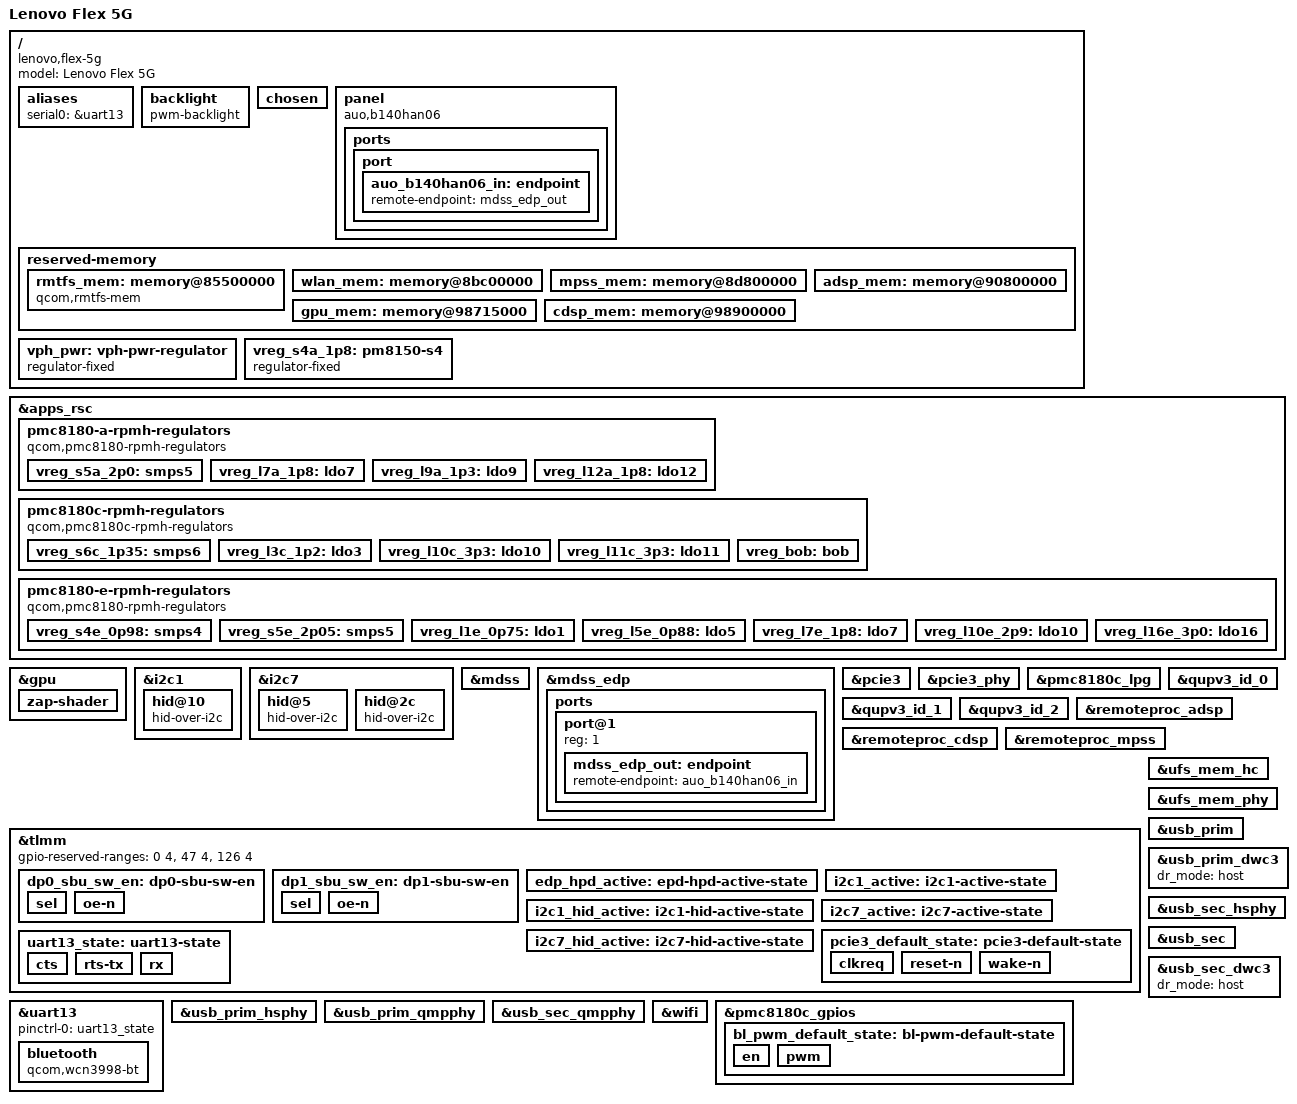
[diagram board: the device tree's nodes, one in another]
// SPDX-License-Identifier: BSD-3-Clause
/*
 * Copyright (c) 2017-2019, The Linux Foundation. All rights reserved.
 * Copyright (c) 2020-2021, Linaro Limited
 */

/dts-v1/;

#include <dt-bindings/regulator/qcom,rpmh-regulator.h>
#include <dt-bindings/gpio/gpio.h>
#include "sc8180x.dtsi"
#include "pmc8180.dtsi"
#include "pmc8180c.dtsi"

/ {
	model = "Lenovo Flex 5G";
	compatible = "lenovo,flex-5g", "qcom,sc8180x";

	aliases {
		serial0 = &uart13;
	};

	backlight: backlight {
		compatible = "pwm-backlight";
		pwms = <&pmc8180c_lpg 4 1000000>;
		enable-gpios = <&pmc8180c_gpios 8 GPIO_ACTIVE_HIGH>;

		pinctrl-names = "default";
		pinctrl-0 = <&bl_pwm_default_state>;
	};

	chosen {
	};

	panel {
		compatible = "auo,b140han06";
		no-hpd;

		backlight = <&backlight>;

		ports {
			port {
				auo_b140han06_in: endpoint {
					remote-endpoint = <&mdss_edp_out>;
				};
			};
		};
	};

	reserved-memory {
		rmtfs_mem: memory@85500000 {
			compatible = "qcom,rmtfs-mem";
			reg = <0x0 0x85500000 0x0 0x200000>;
			no-map;

			qcom,client-id = <1>;
			qcom,vmid = <15>;
		};

		wlan_mem: memory@8bc00000 {
			reg = <0x0 0x8bc00000 0x0 0x180000>;
			no-map;
		};

		mpss_mem: memory@8d800000 {
			reg = <0x0 0x8d800000 0x0 0x3000000>;
			no-map;
		};

		adsp_mem: memory@90800000 {
			reg = <0x0 0x90800000 0x0 0x1c00000>;
			no-map;
		};

		gpu_mem: memory@98715000 {
			reg = <0x0 0x98715000 0x0 0x2000>;
			no-map;
		};

		cdsp_mem: memory@98900000 {
			reg = <0x0 0x98900000 0x0 0x1400000>;
			no-map;
		};
	};

	vph_pwr: vph-pwr-regulator {
		compatible = "regulator-fixed";
		regulator-name = "vph_pwr";
		regulator-min-microvolt = <3700000>;
		regulator-max-microvolt = <3700000>;
	};

	vreg_s4a_1p8: pm8150-s4 {
		compatible = "regulator-fixed";
		regulator-name = "vreg_s4a_1p8";

		regulator-min-microvolt = <1800000>;
		regulator-max-microvolt = <1800000>;

		regulator-always-on;
		regulator-boot-on;

		vin-supply = <&vph_pwr>;
	};
};

&apps_rsc {
	pmc8180-a-rpmh-regulators {
		compatible = "qcom,pmc8180-rpmh-regulators";
		qcom,pmic-id = "a";

		vdd-s5-supply = <&vph_pwr>;
		vdd-l7-l12-l14-l15-supply = <&vreg_s5a_2p0>;

		vreg_s5a_2p0: smps5 {
			regulator-min-microvolt = <2040000>;
			regulator-max-microvolt = <2100000>;
		};

		vreg_l7a_1p8: ldo7 {
			regulator-min-microvolt = <1800000>;
			regulator-max-microvolt = <1800000>;
			regulator-initial-mode = <RPMH_REGULATOR_MODE_HPM>;
		};

		vreg_l9a_1p3: ldo9 {
			regulator-min-microvolt = <1300000>;
			regulator-max-microvolt = <1400000>;
			regulator-initial-mode = <RPMH_REGULATOR_MODE_HPM>;
		};

		vreg_l12a_1p8: ldo12 {
			regulator-min-microvolt = <1800000>;
			regulator-max-microvolt = <1800000>;
			regulator-initial-mode = <RPMH_REGULATOR_MODE_HPM>;
		};
	};

	pmc8180c-rpmh-regulators {
		compatible = "qcom,pmc8180c-rpmh-regulators";
		qcom,pmic-id = "c";

		vdd-s6-supply = <&vph_pwr>;
		vdd-l2-l3-supply = <&vreg_s6c_1p35>;
		vdd-bob-supply = <&vph_pwr>;

		vreg_s6c_1p35: smps6 {
			regulator-min-microvolt = <1350000>;
			regulator-max-microvolt = <1372000>;
			regulator-initial-mode = <RPMH_REGULATOR_MODE_HPM>;
		};

		vreg_l3c_1p2: ldo3 {
			regulator-min-microvolt = <1200000>;
			regulator-max-microvolt = <1200000>;
			regulator-initial-mode = <RPMH_REGULATOR_MODE_HPM>;
		};

		vreg_l10c_3p3: ldo10 {
			regulator-min-microvolt = <3000000>;
			regulator-max-microvolt = <3312000>;
			regulator-initial-mode = <RPMH_REGULATOR_MODE_HPM>;
		};

		vreg_l11c_3p3: ldo11 {
			regulator-min-microvolt = <3000000>;
			regulator-max-microvolt = <3312000>;
			regulator-initial-mode = <RPMH_REGULATOR_MODE_HPM>;
		};

		vreg_bob: bob {
			regulator-min-microvolt = <3296000>;
			regulator-max-microvolt = <3350000>;
			regulator-initial-mode = <RPMH_REGULATOR_MODE_HPM>;
		};
	};

	pmc8180-e-rpmh-regulators {
		compatible = "qcom,pmc8180-rpmh-regulators";
		qcom,pmic-id = "e";

		vdd-s4-supply = <&vph_pwr>;
		vdd-s5-supply = <&vph_pwr>;
		vdd-l2-l10-supply = <&vreg_bob>;
		vdd-l3-l4-l5-l18-supply = <&vreg_s4e_0p98>;
		vdd-l7-l12-l14-l15-supply = <&vreg_s5e_2p05>;
		vdd-l13-l16-l17-supply = <&vreg_bob>;

		vreg_s4e_0p98: smps4 {
			regulator-min-microvolt = <992000>;
			regulator-max-microvolt = <992000>;
			regulator-initial-mode = <RPMH_REGULATOR_MODE_HPM>;
		};

		vreg_s5e_2p05: smps5 {
			regulator-min-microvolt = <2040000>;
			regulator-max-microvolt = <2040000>;
			regulator-initial-mode = <RPMH_REGULATOR_MODE_HPM>;
		};

		vreg_l1e_0p75: ldo1 {
			regulator-min-microvolt = <752000>;
			regulator-max-microvolt = <752000>;
			regulator-initial-mode = <RPMH_REGULATOR_MODE_HPM>;
		};

		vreg_l5e_0p88: ldo5 {
			regulator-min-microvolt = <880000>;
			regulator-max-microvolt = <880000>;
			regulator-initial-mode = <RPMH_REGULATOR_MODE_HPM>;
		};

		vreg_l7e_1p8: ldo7 {
			regulator-min-microvolt = <1800000>;
			regulator-max-microvolt = <1800000>;
			regulator-initial-mode = <RPMH_REGULATOR_MODE_HPM>;
		};

		vreg_l10e_2p9: ldo10 {
			regulator-min-microvolt = <2904000>;
			regulator-max-microvolt = <2904000>;
			regulator-initial-mode = <RPMH_REGULATOR_MODE_HPM>;
		};

		vreg_l16e_3p0: ldo16 {
			regulator-min-microvolt = <3072000>;
			regulator-max-microvolt = <3072000>;
			regulator-initial-mode = <RPMH_REGULATOR_MODE_HPM>;
		};
	};
};

&gpu {
	status = "okay";

	zap-shader {
		memory-region = <&gpu_mem>;
		firmware-name = "qcom/sc8180x/qcdxkmsuc8180.mbn";
	};
};

&i2c1 {
	status = "okay";
	clock-frequency = <100000>;

	pinctrl-names = "default";
	pinctrl-0 = <&i2c1_active>, <&i2c1_hid_active>;

	hid@10 {
		compatible = "hid-over-i2c";
		reg = <0x10>;
		hid-descr-addr = <0x1>;

		interrupts-extended = <&tlmm 122 IRQ_TYPE_LEVEL_LOW>;
	};
};

&i2c7 {
	status = "okay";
	clock-frequency = <100000>;

	pinctrl-names = "default";
	pinctrl-0 = <&i2c7_active>, <&i2c7_hid_active>;

	hid@5 {
		compatible = "hid-over-i2c";
		reg = <0x5>;
		hid-descr-addr = <0x20>;

		interrupts-extended = <&tlmm 37 IRQ_TYPE_LEVEL_LOW>;
	};

	hid@2c {
		compatible = "hid-over-i2c";
		reg = <0x2c>;
		hid-descr-addr = <0x20>;

		interrupts-extended = <&tlmm 24 IRQ_TYPE_LEVEL_LOW>;
	};
};

&mdss {
	status = "okay";
};

&mdss_edp {
	status = "okay";

	data-lanes = <0 1 2 3>;

	pinctrl-names = "default";
	pinctrl-0 = <&edp_hpd_active>;

	ports {
		port@1 {
			reg = <1>;
			mdss_edp_out: endpoint {
				remote-endpoint = <&auo_b140han06_in>;
			};
		};
	};
};

&pcie3 {
	status = "okay";
	perst-gpio = <&tlmm 178 GPIO_ACTIVE_LOW>;
	wake-gpio = <&tlmm 180 GPIO_ACTIVE_HIGH>;
	pinctrl-names = "default";
	pinctrl-0 = <&pcie3_default_state>;
};

&pcie3_phy {
	status = "okay";
	vdda-phy-supply = <&vreg_l5e_0p88>;
	vdda-pll-supply = <&vreg_l3c_1p2>;
};

&pmc8180c_lpg {
	status = "okay";
};

&qupv3_id_0 {
	status = "okay";
};

&qupv3_id_1 {
	status = "okay";
};

&qupv3_id_2 {
	status = "okay";
};

&remoteproc_adsp {
	status = "okay";
	memory-region = <&adsp_mem>;
	firmware-name = "qcom/sc8180x/qcadsp8180.mbn";
};

&remoteproc_cdsp {
	status = "okay";
	memory-region = <&cdsp_mem>;
	firmware-name = "qcom/sc8180x/qccdsp8180.mbn";
};

&remoteproc_mpss {
	status = "okay";
	memory-region = <&mpss_mem>;
	firmware-name = "qcom/sc8180x/qcmpss8180_nm.mbn";
};

&tlmm {
	gpio-reserved-ranges = <0 4>, <47 4>, <126 4>;

	dp0_sbu_sw_en: dp0-sbu-sw-en {
		sel {
			pins = "gpio100";
			function = "gpio";
			output-low;
		};

		oe-n {
			pins = "gpio152";
			function = "gpio";
			output-low;
		};
	};

	dp1_sbu_sw_en: dp1-sbu-sw-en {
		sel {
			pins = "gpio187";
			function = "gpio";
			output-low;
		};

		oe-n {
			pins = "gpio188";
			function = "gpio";
			output-low;
		};
	};

	edp_hpd_active: epd-hpd-active-state {
		pins = "gpio10";
		function = "edp_hot";
	};

	i2c1_active: i2c1-active-state {
		pins = "gpio114", "gpio115";
		function = "qup1";

		bias-pull-up = <1>;
		drive-strength = <2>;
	};

	i2c1_hid_active: i2c1-hid-active-state {
		pins = "gpio122";
		function = "gpio";

		input-enable;
		bias-pull-up;
		drive-strength = <2>;
	};

	i2c7_active: i2c7-active-state {
		pins = "gpio98", "gpio99";
		function = "qup7";

		bias-pull-up;
		drive-strength = <2>;
	};

	i2c7_hid_active: i2c7-hid-active-state {
		pins = "gpio37", "gpio24";
		function = "gpio";

		input-enable;
		bias-pull-up;
		drive-strength = <2>;
	};

	pcie3_default_state: pcie3-default-state {
		clkreq {
			pins = "gpio179";
			function = "pci_e3";
			bias-pull-up;
		};

		reset-n {
			pins = "gpio178";
			function = "gpio";

			drive-strength = <2>;
			output-low;
			bias-pull-down;
		};

		wake-n {
			pins = "gpio180";
			function = "gpio";

			drive-strength = <2>;
			bias-pull-up;
		};
	};

	uart13_state: uart13-state {
		cts {
			pins = "gpio43";
			function = "qup13";
			bias-pull-down;
		};

		rts-tx {
			pins = "gpio44", "gpio45";
			function = "qup13";
			drive-strength = <2>;
			bias-disable;
		};

		rx {
			pins = "gpio46";
			function = "qup13";
			bias-pull-up;
		};
	};
};

&uart13 {
	status = "okay";

	pinctrl-names = "default";
	pinctrl-0 = <&uart13_state>;

	bluetooth {
		compatible = "qcom,wcn3998-bt";

		vddio-supply = <&vreg_s4a_1p8>;
		vddxo-supply = <&vreg_l7a_1p8>;
		vddrf-supply = <&vreg_l9a_1p3>;
		vddch0-supply = <&vreg_l11c_3p3>;
		max-speed = <3200000>;
	};
};

&ufs_mem_hc {
	status = "okay";

	reset-gpios = <&tlmm 190 GPIO_ACTIVE_LOW>;

	vcc-supply = <&vreg_l10e_2p9>;
	vcc-max-microamp = <155000>;

	vccq2-supply = <&vreg_l7e_1p8>;
	vccq2-max-microamp = <425000>;
};

&ufs_mem_phy {
	status = "okay";

	vdda-phy-supply = <&vreg_l5e_0p88>;
	vdda-pll-supply = <&vreg_l3c_1p2>;
};

&usb_prim_hsphy {
	status = "okay";
	vdda-pll-supply = <&vreg_l5e_0p88>;
	vdda18-supply = <&vreg_l12a_1p8>;
	vdda33-supply = <&vreg_l16e_3p0>;
};

&usb_prim_qmpphy {
	status = "okay";
	vdda-phy-supply = <&vreg_l3c_1p2>;
	vdda-pll-supply = <&vreg_l5e_0p88>;
};

&usb_prim {
	status = "okay";
};

&usb_prim_dwc3 {
	dr_mode = "host";
};

&usb_sec_hsphy {
	status = "okay";
	vdda-pll-supply = <&vreg_l5e_0p88>;
	vdda18-supply = <&vreg_l12a_1p8>;
	vdda33-supply = <&vreg_l16e_3p0>;
};

&usb_sec_qmpphy {
	status = "okay";
	vdda-phy-supply = <&vreg_l3c_1p2>;
	vdda-pll-supply = <&vreg_l5e_0p88>;
};

&usb_sec {
	status = "okay";
};

&usb_sec_dwc3 {
	dr_mode = "host";
};

&wifi {
	status = "okay";

	memory-region = <&wlan_mem>;

	vdd-0.8-cx-mx-supply = <&vreg_l1e_0p75>;
	vdd-1.8-xo-supply = <&vreg_l7a_1p8>;
	vdd-1.3-rfa-supply = <&vreg_l9a_1p3>;
	vdd-3.3-ch0-supply = <&vreg_l11c_3p3>;
	vdd-3.3-ch1-supply = <&vreg_l10c_3p3>;
};

/* PINCTRL */

&pmc8180c_gpios {
	bl_pwm_default_state: bl-pwm-default-state {
		en {
			pins = "gpio8";
			function = "normal";
		};

		pwm {
			pins = "gpio10";
			function = "func1";
		};
	};
};
